# LPC13Uxx register map
File version: 1
CPU: CM3 r2p1, little endian, no MPU, no FPU, 3 interrupt priority bits
Registers are 32-bit, read-write, reset 0x0 unless marked. A register's access mark holds for its fields unless they carry their own. Offsets are from the block's base; [hi:lo] are bit positions; {n}, {i} and the like mark numbered series; 'fields as' and 'values as' point back to an identical list.

## USART
Base 0x40008000
0x00 RBR ro reset not defined read-modifies — Receiver Buffer Register. Contains the next received character to be read. (DLAB=0)
  [7:0] RBR — The USART Receiver Buffer Register contains the oldest received byte in the USART RX FIFO.
0x00 THR wo reset not defined read-modifies (alternate view of RBR) — Transmit Holding Register. The next character to be transmitted is written here. (DLAB=0)
  [7:0] THR — Writing to the USART Transmit Holding Register causes the data to be stored in the USART transmit FIFO. The byte will be sent when it is the oldest byte in the FIFO and the transmitter is available.
0x00 DLL reset 0x1 (alternate view of RBR) — Divisor Latch LSB. Least significant byte of the baud rate divisor value. The full divisor is used to generate a baud rate from the fractional rate divider. (DLAB=1)
  [7:0] DLLSB — The USART Divisor Latch LSB Register, along with the DLM register, determines the baud rate of the USART.
0x04 DLM — Divisor Latch MSB. Most significant byte of the baud rate divisor value. The full divisor is used to generate a baud rate from the fractional rate divider. (DLAB=1)
  [7:0] DLMSB — The USART Divisor Latch MSB Register, along with the DLL register, determines the baud rate of the USART.
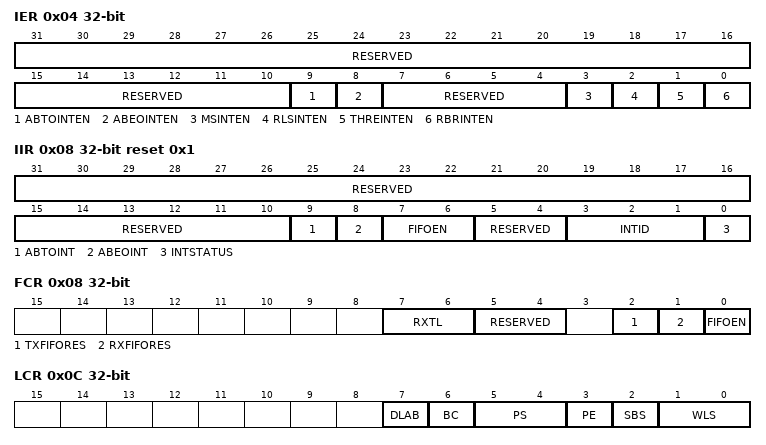
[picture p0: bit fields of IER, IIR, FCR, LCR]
0x04 IER (alternate view of DLM) — Interrupt Enable Register. Contains individual interrupt enable bits for the 7 potential USART interrupts. (DLAB=0)
  [31:10] RESERVED — Reserved, user software should not write ones to reserved bits. The value read from a reserved bit is not defined.
  [9] ABTOINTEN — Enables the auto-baud time-out interrupt.
    0=DISABLE_AUTO_BAUD_TI (Disable auto-baud time-out Interrupt.); 1=ENABLE_AUTO_BAUD_TIM (Enable auto-baud time-out Interrupt.)
  [8] ABEOINTEN — Enables the end of auto-baud interrupt.
    0=DISABLE_END_OF_AUTO_ (Disable end of auto-baud Interrupt.); 1=ENABLE_END_OF_AUTO_B (Enable end of auto-baud Interrupt.)
  [7:4] RESERVED — Reserved, user software should not write ones to reserved bits. The value read from a reserved bit is not defined.
  [3] MSINTEN — Enables the Modem Status interrupt. The components of this interrupt can be read from the MSR.
    0=DISABLE_THE_MS_INTER (Disable the MS interrupt.); 1=ENABLE_THE_MS_INTERR (Enable the MS interrupt.)
  [2] RLSINTEN — Enables the Receive Line Status interrupt. The status of this interrupt can be read from LSR\[4:1\].
    0=DISABLE_THE_RLS_INTE (Disable the RLS interrupt.); 1=ENABLE_THE_RLS_INTER (Enable the RLS interrupt.)
  [1] THREINTEN — THRE Interrupt Enable. Enables the THRE interrupt. The status of this interrupt can be read from LSR\[\5\].
    0=DISABLE_THE_THRE_INT (Disable the THRE interrupt.); 1=ENABLE_THE_THRE_INTE (Enable the THRE interrupt.)
  [0] RBRINTEN — RBR Interrupt Enable. Enables the Receive Data Available interrupt. It also controls the Character Receive Time-out interrupt.
    0=DISABLE_THE_RDA_INTE (Disable the RDA interrupt.); 1=ENABLE_THE_RDA_INTER (Enable the RDA interrupt.)
0x08 IIR ro reset 0x1 — Interrupt ID Register. Identifies which interrupt(s) are pending.
  [31:10] RESERVED — Reserved, user software should not write ones to reserved bits. The value read from a reserved bit is not defined.
  [9] ABTOINT — Auto-baud time-out interrupt. True if auto-baud has timed out and interrupt is enabled.
  [8] ABEOINT — End of auto-baud interrupt. True if auto-baud has finished successfully and interrupt is enabled.
  [7:6] FIFOEN — These bits are equivalent to FCR\[0\].
  [5:4] RESERVED — Reserved, user software should not write ones to reserved bits. The value read from a reserved bit is not defined.
  [3:1] INTID — Interrupt identification. IER\[3:1\] identifies an interrupt corresponding to the USART Rx FIFO. All other values of IER\[3:1\] not listed below are reserved.
    3=1_RECEIVE_LINE_S (1 - Receive Line Status (RLS).); 2=2A_RECEIVE_DATA_AV (2a - Receive Data Available (RDA).); 6=2B_CHARACTER_TIME_ (2b - Character Time-out Indicator (CTI).); 1=3_THRE_INTERRUPT; 0=4_MODEM_STATUS
  [0] INTSTATUS — Interrupt status. Note that IIR\[0\] is active low. The pending interrupt can be determined by evaluating IIR\[3:1\].
    0=AT_LEAST_ONE_INTERRU (At least one interrupt is pending.); 1=NO_INTERRUPT_IS_PEND (No interrupt is pending.)
0x08 FCR wo — FIFO Control Register. Controls USART FIFO usage and modes.
  [7:6] RXTL — RX Trigger Level. These two bits determine how many receiver USART FIFO characters must be written before an interrupt is activated.
    0=TRIGGER_LEVEL_0_1_C (Trigger level 0 (1 character or 0x01).); 1=TRIGGER_LEVEL_1_4_C (Trigger level 1 (4 characters or 0x04).); 2=TRIGGER_LEVEL_2_8_C (Trigger level 2 (8 characters or 0x08).); 3=TRIGGER_LEVEL_3_14_ (Trigger level 3 (14 characters or 0x0E).)
  [5:4] RESERVED — Reserved, user software should not write ones to reserved bits. The value read from a reserved bit is not defined.
  [2] TXFIFORES — TX FIFO Reset
    0=NO_IMPACT (No impact on either of USART FIFOs.); 1=CLEAR (Writing a logic 1 to FCR\[2\] will clear all bytes in USART TX FIFO, reset the pointer logic. This bit is self-clearing.)
  [1] RXFIFORES — RX FIFO Reset
    0=NO_IMPACT (No impact on either of USART FIFOs.); 1=CLEAR (Writing a logic 1 to FCR\[1\] will clear all bytes in USART Rx FIFO, reset the pointer logic. This bit is self-clearing.)
  [0] FIFOEN — FIFO enable
    0=DISABLED (USART FIFOs are disabled. Must not be used in the application.); 1=ENABLED (Active high enable for both USART Rx and TX FIFOs and FCR\[7:1\] access. This bit must be set for proper USART operation. Any transition on this bit will automatically clear the USART FIFOs.)
0x0C LCR — Line Control Register. Contains controls for frame formatting and break generation.
  [7] DLAB — Divisor Latch Access Bit
    0=DISABLE_ACCESS_TO_DI (Disable access to Divisor Latches.); 1=ENABLE_ACCESS_TO_DIV (Enable access to Divisor Latches.)
  [6] BC — Break Control
    0=DISABLE_BREAK_TRANSM (Disable break transmission.); 1=ENABLE_BREAK_TRANSMI (Enable break transmission. Output pin USART TXD is forced to logic 0 when LCR\[6\] is active high.)
  [5:4] PS — Parity Select
    0=ODD_PARITY_NUMBER_O (Odd parity. Number of 1s in the transmitted character and the attached parity bit will be odd.); 1=EVEN_PARITY_NUMBER_ (Even Parity. Number of 1s in the transmitted character and the attached parity bit will be even.); 2=FORCED_1_STICK_PARIT (Forced 1 stick parity.); 3=FORCED_0_STICK_PARIT (Forced 0 stick parity.)
  [3] PE — Parity Enable
    0=DISABLE_PARITY_GENER (Disable parity generation and checking.); 1=ENABLE_PARITY_GENERA (Enable parity generation and checking.)
  [2] SBS — Stop Bit Select
    0=1_STOP_BIT_; 1=2_STOP_BITS_1_5_IF_ (2 stop bits (1.5 if LCR\[1:0\]=00).)
  [1:0] WLS — Word Length Select
    {v}={v+5}_BIT_CHARACTER_LENG ({v+5}-bit character length.) (v=0..3)
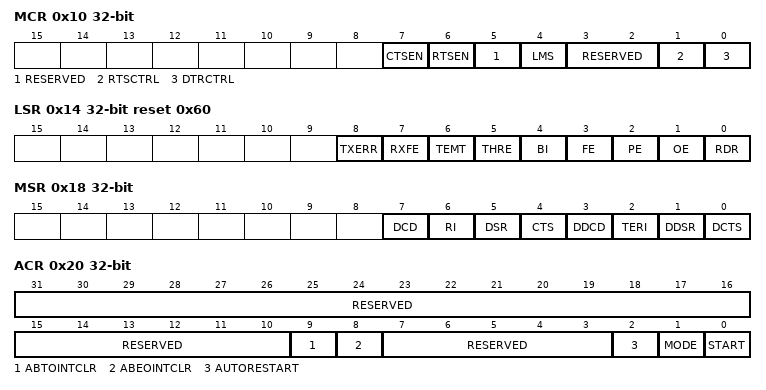
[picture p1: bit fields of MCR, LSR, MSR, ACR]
0x10 MCR — Modem Control Register.
  [7] CTSEN — CTS enable
    0=DISABLE_AUTO_CTS_FLO (Disable auto-cts flow control.); 1=ENABLE_AUTO_CTS_FLOW (Enable auto-cts flow control.)
  [6] RTSEN — RTS enable
    0=DISABLE_AUTO_RTS_FLO (Disable auto-rts flow control.); 1=ENABLE_AUTO_RTS_FLOW (Enable auto-rts flow control.)
  [5] RESERVED — Reserved, user software should not write ones to reserved bits. The value read from a reserved bit is not defined.
  [4] LMS — Loopback Mode Select. The modem loopback mode provides a mechanism to perform diagnostic loopback testing. Serial data from the transmitter is connected internally to serial input of the receiver. Input pin, RXD, has no effect on loopback and output pin, TXD is held in marking state. The DSR, CTS, DCD, and RI pins are ignored. Externally, DTR and RTS are set inactive. Internally, the upper four bits of the MSR are driven by the lower four bits of the MCR. This permits modem status interrupts to be generated in loopback mode by writing the lower four bits of MCR.
    0=DISABLE_MODEM_LOOPBA (Disable modem loopback mode.); 1=ENABLE_MODEM_LOOPBAC (Enable modem loopback mode.)
  [3:2] RESERVED — Reserved, user software should not write ones to reserved bits. The value read from a reserved bit is not defined.
  [1] RTSCTRL — Source for modem output pin RTS. This bit reads as 0 when modem loopback mode is active.
  [0] DTRCTRL — Source for modem output pin DTR. This bit reads as 0 when modem loopback mode is active.
0x14 LSR ro reset 0x60 read-modifies — Line Status Register. Contains flags for transmit and receive status, including line errors.
  [8] TXERR — Tx Error. In smart card T=0 operation, this bit is set when the smart card has NACKed a transmitted character, one more than the number of times indicated by the TXRETRY field.
  [7] RXFE — Error in RX FIFO. LSR\[7\] is set when a character with a RX error such as framing error, parity error or break interrupt, is loaded into the RBR. This bit is cleared when the LSR register is read and there are no subsequent errors in the USART FIFO.
    0=NO_ERROR (RBR contains no USART RX errors or FCR\[0\]=0.); 1=ERRO (USART RBR contains at least one USART RX error.)
  [6] TEMT — Transmitter Empty. TEMT is set when both THR and TSR are empty; TEMT is cleared when either the TSR or the THR contain valid data.
    0=VALID_D (THR and/or the TSR contains valid data.); 1=EMPTY (THR and the TSR are empty.)
  [5] THRE — Transmitter Holding Register Empty. THRE is set immediately upon detection of an empty USART THR and is cleared on a THR write.
    0=THR_CONTAINS_VALID_D (THR contains valid data.); 1=THR_IS_EMPTY_
  [4] BI — Break Interrupt. When RXD1 is held in the spacing state (all zeros) for one full character transmission (start, data, parity, stop), a break interrupt occurs. Once the break condition has been detected, the receiver goes idle until RXD1 goes to marking state (all ones). A LSR read clears this status bit. The time of break detection is dependent on FCR\[0\]. Note: The break interrupt is associated with the character at the top of the USART RBR FIFO.
    0=INACTIVE (Break interrupt status is inactive.); 1=ACTIVE (Break interrupt status is active.)
  [3] FE — Framing Error. When the stop bit of a received character is a logic 0, a framing error occurs. A LSR read clears LSR\[3\]. The time of the framing error detection is dependent on FCR0. Upon detection of a framing error, the RX will attempt to re-synchronize to the data and assume that the bad stop bit is actually an early start bit. However, it cannot be assumed that the next received byte will be correct even if there is no Framing Error. Note: A framing error is associated with the character at the top of the USART RBR FIFO.
    0=INACTIVE (Framing error status is inactive.); 1=ACTIVE (Framing error status is active.)
  [2] PE — Parity Error. When the parity bit of a received character is in the wrong state, a parity error occurs. A LSR read clears LSR\[2\]. Time of parity error detection is dependent on FCR\[0\]. Note: A parity error is associated with the character at the top of the USART RBR FIFO.
    0=INACTIVE (Parity error status is inactive.); 1=ACTIVE (Parity error status is active.)
  [1] OE — Overrun Error. The overrun error condition is set as soon as it occurs. A LSR read clears LSR\[1\]. LSR\[1\] is set when USART RSR has a new character assembled and the USART RBR FIFO is full. In this case, the USART RBR FIFO will not be overwritten and the character in the USART RSR will be lost.
    0=INACTIVE (Overrun error status is inactive.); 1=ACTIVE (Overrun error status is active.)
  [0] RDR — Receiver Data Ready:LSR\[0\] is set when the RBR holds an unread character and is cleared when the USART RBR FIFO is empty.
    0=RBR_IS_EMPTY_; 1=RBR_CONTAINS_VALID_D (RBR contains valid data.)
0x18 MSR ro read-modifies — Modem Status Register.
  [7] DCD — Data Carrier Detect State. Complement of input DCD. This bit is connected to MCR\[3\] in modem loopback mode.
  [6] RI — Ring Indicator State. Complement of input RI. This bit is connected to MCR\[2\] in modem loopback mode.
  [5] DSR — Data Set Ready State. Complement of input signal DSR. This bit is connected to MCR\[0\] in modem loopback mode.
  [4] CTS — Clear To Send State. Complement of input signal CTS. This bit is connected to MCR\[1\] in modem loopback mode.
  [3] DDCD — Delta DCD. Set upon state change of input DCD. Cleared on an MSR read.
    0=NO_CHANGE_DETECTED_O (No change detected on modem input, DCD.); 1=STATE_CHANGE_DETECTE (State change detected on modem input, DCD.)
  [2] TERI — Trailing Edge RI. Set upon low to high transition of input RI. Cleared on an MSR read.
    0=NO_CHANGE_DETECTED_O (No change detected on modem input, RI.); 1=LOW_TO_HIGH_TRANSITI (Low-to-high transition detected on RI.)
  [1] DDSR — Delta DSR. Set upon state change of input DSR. Cleared on an MSR read.
    0=NO_CHANGE_DETECTED_O (No change detected on modem input, DSR.); 1=STATE_CHANGE_DETECTE (State change detected on modem input, DSR.)
  [0] DCTS — Delta CTS. Set upon state change of input CTS. Cleared on an MSR read.
    0=NO_CHANGE_DETECTED_O (No change detected on modem input, CTS.); 1=STATE_CHANGE_DETECTE (State change detected on modem input, CTS.)
0x1C SCR — Scratch Pad Register. Eight-bit temporary storage for software.
  [7:0] PAD — A readable, writable byte.
0x20 ACR — Auto-baud Control Register. Contains controls for the auto-baud feature.
  [31:10] RESERVED — Reserved, user software should not write ones to reserved bits. The value read from a reserved bit is not defined.
  [9] ABTOINTCLR — Auto-baud time-out interrupt clear bit (write only accessible).
    0=NO_IMPACT (Writing a 0 has no impact.); 1=CLEAR (Writing a 1 will clear the corresponding interrupt in the IIR.)
  [8] ABEOINTCLR — End of auto-baud interrupt clear bit (write only accessible).
    values as ABTOINTCLR
  [7:3] RESERVED — Reserved, user software should not write ones to reserved bits. The value read from a reserved bit is not defined.
  [2] AUTORESTART — Start mode
    0=NO_RESTART; 1=RESTART_IN_CASE_OF_T (Restart in case of time-out (counter restarts at next USART Rx falling edge))
  [1] MODE — Auto-baud mode select bit.
    0=MODE_0_; 1=MODE_1_
  [0] START — This bit is automatically cleared after auto-baud completion.
    0=AUTO_BAUD_STOP_AUTO (Auto-baud stop (auto-baud is not running).); 1=AUTO_BAUD_START_AUT (Auto-baud start (auto-baud is running). Auto-baud run bit. This bit is automatically cleared after auto-baud completion.)
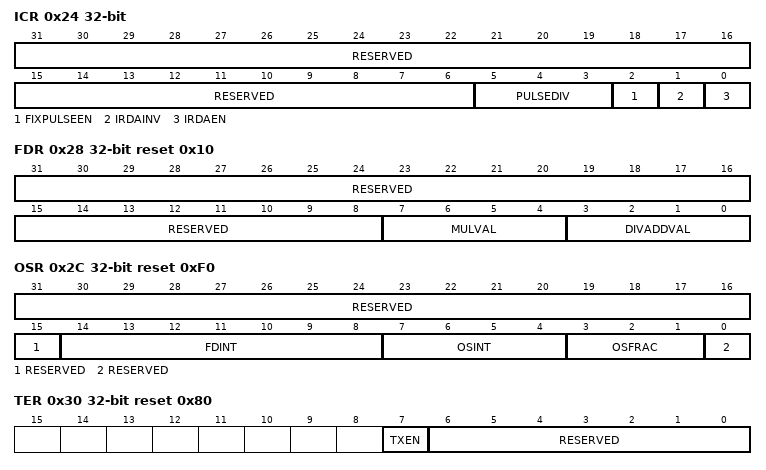
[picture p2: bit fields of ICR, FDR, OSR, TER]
0x24 ICR — IrDA Control Register. Enables and configures the IrDA (remote control) mode.
  [31:6] RESERVED — Reserved, user software should not write ones to reserved bits. The value read from a reserved bit is not defined.
  [5:3] PULSEDIV — Configures the pulse width when FixPulseEn = 1.
    0=3_DIV_16_X_BAUD_RATE (3 / (16 x baud rate)); 1=2_X_TPCLK; 2=4_X_TPCLK; 3=8_X_TPCLK; 4=16_X_TPCLK; 5=32_X_TPCLK; 6=64_X_TPCLK; 7=128_X_TPCLK
  [2] FIXPULSEEN — IrDA fixed pulse width mode.
    0=DISABLED (IrDA fixed pulse width mode disabled.); 1=ENABLED (IrDA fixed pulse width mode enabled.)
  [1] IRDAINV — Serial input inverter
    0=INVERTED (The serial input is not inverted.); 1=NOT_INVERTED (The serial input is inverted. This has no effect on the serial output.)
  [0] IRDAEN — IrDA mode enable
    0=IRDA_MODE_IS_DISABLE (IrDA mode is disabled, USARTn acts as a standard USART.); 1=IRDA_MODE_IS_ENABLED
0x28 FDR reset 0x10 — Fractional Divider Register. Generates a clock input for the baud rate divider.
  [31:8] RESERVED — Reserved, user software should not write ones to reserved bits. The value read from a reserved bit is not defined.
  [7:4] MULVAL — Baud rate pre-scaler multiplier value. This field must be greater or equal 1 for USART to operate properly, regardless of whether the fractional baud rate generator is used or not.
  [3:0] DIVADDVAL — Baud rate generation pre-scaler divisor value. If this field is 0, fractional baud rate generator will not impact the USART baud rate.
0x2C OSR reset 0xF0 — Oversampling Register. Controls the degree of oversampling during each bit time.
  [31:15] RESERVED — Reserved, user software should not write ones to reserved bits. The value read from a reserved bit is not defined.
  [14:8] FDINT — In Smart Card mode, these bits act as a more-significant extension of the OSint field, allowing an oversampling ratio up to 2048 as required by ISO7816-3. In Smart Card mode, bits 14:4 should initially be set to 371, yielding an oversampling ratio of 372.
  [7:4] OSINT — Integer part of the oversampling ratio, minus 1. The reset values equate to the normal operating mode of 16 input clocks per bit time.
  [3:1] OSFRAC — Fractional part of the oversampling ratio, in units of 1/8th of an input clock period. (001 = 0.125, ..., 111 = 0.875)
  [0] RESERVED — Reserved, user software should not write ones to reserved bits. The value read from a reserved bit is not defined.
0x30 TER reset 0x80 — Transmit Enable Register. Turns off USART transmitter for use with software flow control.
  [7] TXEN — When this bit is 1, as it is after a Reset, data written to the THR is output on the TXD pin as soon as any preceding data has been sent. If this bit cleared to 0 while a character is being sent, the transmission of that character is completed, but no further characters are sent until this bit is set again. In other words, a 0 in this bit blocks the transfer of characters from the THR or TX FIFO into the transmit shift register. Software can clear this bit when it detects that the a hardware-handshaking TX-permit signal (CTS) has gone false, or with software handshaking, when it receives an XOFF character (DC3). Software can set this bit again when it detects that the TX-permit signal has gone true, or when it receives an XON (DC1) character.
  [6:0] RESERVED — Reserved, user software should not write ones to reserved bits. The value read from a reserved bit is not defined.
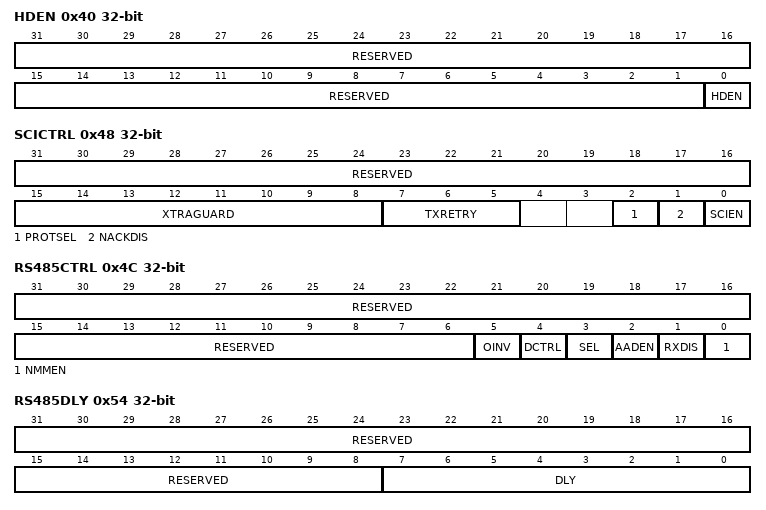
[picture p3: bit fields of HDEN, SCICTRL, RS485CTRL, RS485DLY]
0x40 HDEN — Half duplex enable register.
  [31:1] RESERVED — Reserved, user software should not write ones to reserved bits. The value read from a reserved bit is not defined.
  [0] HDEN — Half-duplex mode enable
    0=DISABLE_HALF_DUPLEX_ (Disable half-duplex mode.); 1=ENABLE_HALF_DUPLEX_M (Enable half-duplex mode.)
0x48 SCICTRL — Smart Card Interface Control register. Enables and configures the Smart Card Interface feature.
  [31:16] RESERVED — Reserved, user software should not write ones to reserved bits. The value read from a reserved bit is not defined.
  [15:8] XTRAGUARD — When the protocol selection T bit (above) is 0, this field indicates the number of bit times (ETUs) by which the guard time after a character transmitted by the USART should exceed the nominal 2 bit times. 0xFF in this field may indicate that there is just a single bit after a character and 11 bit times/character
  [7:5] TXRETRY — When the protocol selection T bit (above) is 0, the field controls the maximum number of retransmissions that the USART will attempt if the remote device signals NACK. When NACK has occurred this number of times plus one, the Tx Error bit in the LSR is set, an interrupt is requested if enabled, and the USART is locked until the FIFO is cleared.
  [2] PROTSEL — Protocol selection as defined in the ISO7816-3 standard.
    0=T_EQ_0 (T = 0); 1=T_EQ_1 (T = 1)
  [1] NACKDIS — NACK response disable. Only applicable in T=0.
    0=ENABLED (A NACK response is enabled.); 1=DISABLED (A NACK response is inhibited.)
  [0] SCIEN — Smart Card Interface Enable.
    0=SMART_CARD_INTERFACE (Smart card interface disabled.); 1=ASYNCHRONOUS_HALF_DU (Asynchronous half duplex smart card interface is enabled.)
0x4C RS485CTRL — RS-485/EIA-485 Control. Contains controls to configure various aspects of RS-485/EIA-485 modes.
  [31:6] RESERVED — Reserved, user software should not write ones to reserved bits. The value read from a reserved bit is not defined.
  [5] OINV — Polarity control. This bit reverses the polarity of the direction control signal on the RTS (or DTR) pin.
    0=LOW (The direction control pin will be driven to logic 0 when the transmitter has data to be sent. It will be driven to logic 1 after the last bit of data has been transmitted.); 1=HIGH (The direction control pin will be driven to logic 1 when the transmitter has data to be sent. It will be driven to logic 0 after the last bit of data has been transmitted.)
  [4] DCTRL — Auto direction control enable.
    0=DISABLE_AUTO_DIRECTI (Disable Auto Direction Control.); 1=ENABLE_AUTO_DIRECTIO (Enable Auto Direction Control.)
  [3] SEL — Select direction control pin
    0=RTS (If direction control is enabled (bit DCTRL = 1), pin RTS is used for direction control.); 1=DTR (If direction control is enabled (bit DCTRL = 1), pin DTR is used for direction control.)
  [2] AADEN — AAD enable.
    0=AUTO_ADDRESS_DETECT_DISABLED (Auto Address Detect (AAD) is disabled.); 1=AUTO_ADDRESS_DETECT_ENABLED (Auto Address Detect (AAD) is enabled.)
  [1] RXDIS — Receiver enable.
    0=THE_RECEIVER_IS_ENAB (The receiver is enabled.); 1=THE_RECEIVER_IS_DISA (The receiver is disabled.)
  [0] NMMEN — NMM enable.
    0=RS_485_EIA_485_NORMAL_DISABLED (RS-485/EIA-485 Normal Multidrop Mode (NMM) is disabled.); 1=RS_485_EIA_485_NORMAL_ENABLED (RS-485/EIA-485 Normal Multidrop Mode (NMM) is enabled. In this mode, an address is detected when a received byte causes the USART to set the parity error and generate an interrupt.)
0x50 RS485ADRMATCH — RS-485/EIA-485 address match. Contains the address match value for RS-485/EIA-485 mode.
  [7:0] ADRMATCH — Contains the address match value.
0x54 RS485DLY — RS-485/EIA-485 direction control delay.
  [31:8] RESERVED — Reserved, user software should not write ones to reserved bits. The value read from a reserved bit is not defined.
  [7:0] DLY — Contains the direction control (RTS or DTR) delay value. This register works in conjunction with an 8-bit counter.
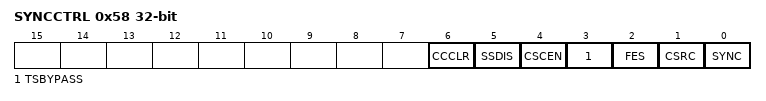
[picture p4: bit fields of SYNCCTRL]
0x58 SYNCCTRL — Synchronous mode control register.
  [6] CCCLR — Continuous clock clear
    0=CSCEN_IS_UNDER_SOFTW (CSCEN is under software control.); 1=HARDWARE_CLEARS_CSCE (Hardware clears CSCEN after each character is received.)
  [5] SSDIS — Start/stop bits
    0=SEND_START_STOP (Send start and stop bits as in other modes.); 1=NOT_SEND_START_STOP (Do not send start/stop bits.)
  [4] CSCEN — Continuous master clock enable (used only when CSRC is 1)
    0=SCLK_CYCLES_ONLY_WHE (SCLK cycles only when characters are being sent on TxD); 1=SCLK_RUNS_CONTINUOUS (SCLK runs continuously (characters can be received on RxD independently from transmission on TxD))
  [3] TSBYPASS — Transmit synchronization bypass in synchronous slave mode.
    0=SYNC (The input clock is synchronized prior to being used in clock edge detection logic); 1=NOSYNC (The input clock is not synchronized prior to being used in clock edge detection logic. This allows for a high er input clock rate at the expense of potential metastability.)
  [2] FES — Falling edge sampling.
    0=RISING (RxD is sampled on the rising edge of SCLK); 1=FALLING (RxD is sampled on the falling edge of SCLK)
  [1] CSRC — Clock source select.
    0=SYNCHRONOUS_SLAVE_MO (Synchronous slave mode (SCLK in)); 1=SYNCHRONOUS_MASTER_M (Synchronous master mode (SCLK out))
  [0] SYNC — Enables synchronous mode.
    0=DISABLED; 1=ENABLED
